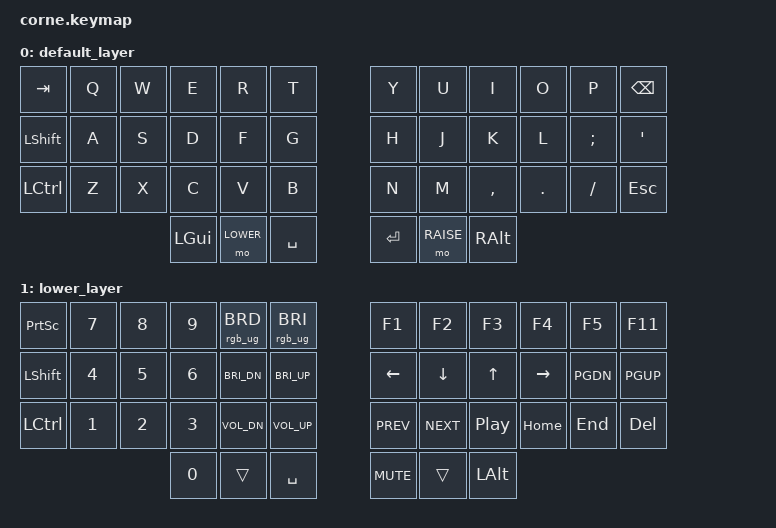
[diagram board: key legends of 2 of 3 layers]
 
/*
 * Copyright (c) 2020 The ZMK Contributors
 *
 * SPDX-License-Identifier: MIT
 */

#include <behaviors.dtsi>
#include <dt-bindings/zmk/keys.h>
#include <dt-bindings/zmk/bt.h>
#include <dt-bindings/zmk/rgb.h>

#define DEFAULT 0
#define LOWER 1
#define RAISE 2

&led_strip {
    chain-length = <27>;
    // 21 backlight + 6 glowlight
};

/ {
        keymap {
                compatible = "zmk,keymap";

                default_layer {
// -----------------------------------------------------------------------------------------
// |  TAB |  Q  |  W  |  E  |  R  |  T  |   |  Y  |  U   |  I  |  O  |  P  | BKSP |
// | SHFT |  A  |  S  |  D  |  F  |  G  |   |  H  |  J   |  K  |  L  |  ;  |  '   |
// | CTRL |  Z  |  X  |  C  |  V  |  B  |   |  N  |  M   |  ,  |  .  |  /  | ESC  |
//                    | GUI | LWR | SPC |   | ENT | RSE  | ALT |
                        bindings = <
   &kp TAB   &kp Q &kp W &kp E &kp R &kp T   &kp Y &kp U  &kp I     &kp O   &kp P    &kp BSPC
   &kp LSHFT &kp A &kp S &kp D &kp F &kp G   &kp H &kp J  &kp K     &kp L   &kp SEMI &kp SQT
   &kp LCTRL &kp Z &kp X &kp C &kp V &kp B   &kp N &kp M  &kp COMMA &kp DOT &kp FSLH &kp ESC
                  &kp LGUI &mo LOWER &kp SPACE   &kp RET &mo RAISE &kp RALT
                        >;
                };

                lower_layer {
// -----------------------------------------------------------------------------------------
// | SHOT |  7  |  8  |  9  | RGB- | RGB+ |   | F1   | F2   | F3   | F4    | F5   | F11  |
// | SHFT |  4  |  5  |  6  | DISP-| DISP+|   | LEFT | DOWN | UP   | RIGHT | PGDN | PGUP |
// | CTRL |  1  |  2  |  3  | VOL- | VOL+ |   | PREV | NEXT | PLAY | HOME  | END  | DEL  |
//                    |  0  |     | SPC |   | MUTE |     | ALT |
                        bindings = <
   &kp PSCRN &kp N7 &kp N8 &kp N9 &rgb_ug RGB_BRD &rgb_ug RGB_BRI   &kp F1     &kp F2   &kp F3   &kp F4    &kp F5    &kp F11
   &kp LSHFT &kp N4 &kp N5 &kp N6 &kp C_BRI_DN    &kp C_BRI_UP      &kp LEFT   &kp DOWN &kp UP   &kp RIGHT &kp PGDN  &kp PGUP
   &kp LCTRL &kp N1 &kp N2 &kp N3 &kp C_VOL_DN    &kp C_VOL_UP      &kp C_PREV &kp C_NEXT &kp C_PP  &kp  HOME &kp END &kp DEL
                                    &kp N0 &trans &kp SPACE   &kp C_MUTE &trans &kp LALT
                        >;
                };

                raise_layer {
// -----------------------------------------------------------------------------------------
// | RALT |  1   |  2   |  3   |  4    |  5    |     |  6     |  7  |  8  |  9  |  0  | DEL |
// | SHFT | BT0  | BT1  | BT2  |       |       |     |  -     |  =  |  [  |  ]  |  \  |  `  |
// | CTRL | EFF+ | HUE+ | SPD+ | SAT+  |       |     | BTCLR  |  _  |  +  |  {  |  }  |  |  |  ~  |
//                    | RGB_TOG |     | SPC |   | ENT |     | ALT |
                        bindings = <
   &kp GRAVE &kp N1 &kp N2 &kp N3 &kp N4 &kp N5   &kp N6 &kp N7 &kp N8 &kp N9 &kp N0 &kp DEL
   &kp LSHFT &bt BT_SEL 0 &bt BT_SEL 1 &bt BT_SEL 2 &none &none   &kp MINUS &kp EQUAL &kp LBKT &kp RBKT &kp BSLH &kp GRAVE
   &kp LCTRL &rgb_ug RGB_EFF &rgb_ug RGB_HUI &rgb_ug RGB_SPI &rgb_ug RGB_SAI &none   &bt BT_CLR &kp UNDER &kp PLUS &kp LBRC &kp RBRC &kp PIPE &kp TILDE
                                    &rgb_ug RGB_TOG &trans &kp SPACE   &kp RET &trans &kp RALT
                        >;
                };
        };
};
